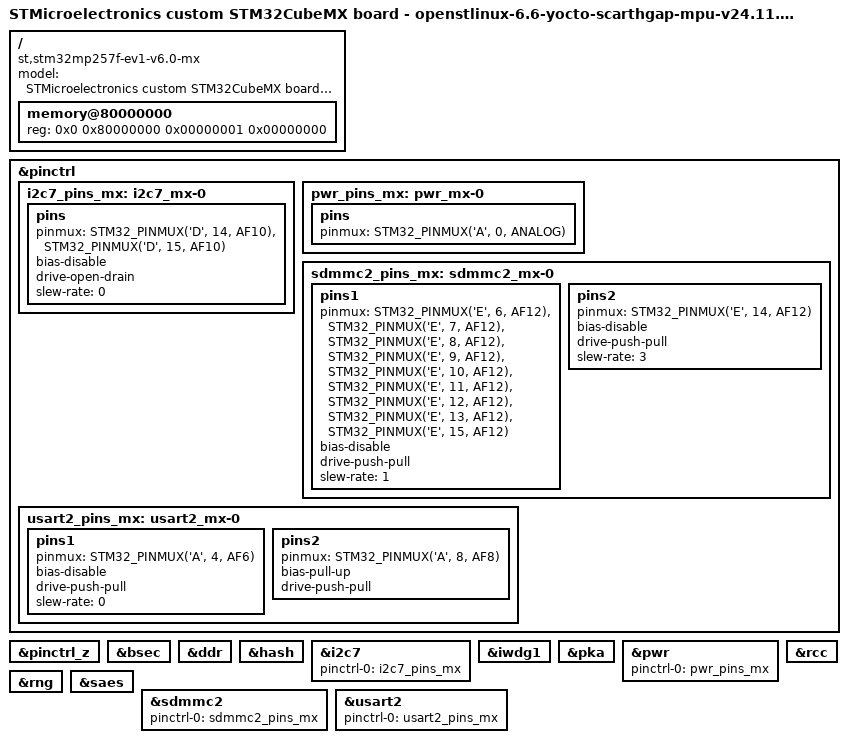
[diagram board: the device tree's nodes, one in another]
// SPDX-License-Identifier: (GPL-2.0-or-later OR BSD-3-Clause)
/*
 * Copyright (C) 2024, STMicroelectronics - All Rights Reserved
 * Author: STM32CubeMX code generation for STMicroelectronics.
 */

/* For more information on Device Tree configuration, please refer to
 * https://wiki.st.com/stm32mpu/wiki/Category:Device_tree_configuration
 */

/dts-v1/;

#include <dt-bindings/pinctrl/stm32-pinfunc.h>
#include <dt-bindings/clock/stm32mp25-clksrc.h>
#include "stm32mp25-mx.dtsi"

#include "stm32mp257.dtsi"
#include "stm32mp25xf.dtsi"
#include "stm32mp257f-ev1-v6.0-mx-rcc.dtsi"
#include "stm32mp25xxai-pinctrl.dtsi"
#include "stm32mp25-ddr.dtsi"

/* USER CODE BEGIN includes */
/* USER CODE END includes */

/ {
	model = "STMicroelectronics custom STM32CubeMX board - openstlinux-6.6-yocto-scarthgap-mpu-v24.11.06";
	compatible = "st,stm32mp257f-ev1-v6.0-mx", "st,stm32mp257";

	memory@80000000 {
		device_type = "memory";
		reg = <0x0 0x80000000 0x00000001 0x00000000>;

		/* USER CODE BEGIN memory */
		/* USER CODE END memory */
	};

	/* USER CODE BEGIN root */
	/* USER CODE END root */

}; /*root*/

&pinctrl {
	i2c7_pins_mx: i2c7_mx-0 {
		pins {
			pinmux = <STM32_PINMUX('D', 14, AF10)>, /* I2C7_SDA */
					 <STM32_PINMUX('D', 15, AF10)>; /* I2C7_SCL */
			bias-disable;
			drive-open-drain;
			slew-rate = <0>;
		};
	};

	pwr_pins_mx: pwr_mx-0 {
		pins {
			pinmux = <STM32_PINMUX('A', 0, ANALOG)>; /* PWR_WKUP1 */
		};
	};

	sdmmc2_pins_mx: sdmmc2_mx-0 {
		pins1 {
			pinmux = <STM32_PINMUX('E', 6, AF12)>, /* SDMMC2_D6 */
					 <STM32_PINMUX('E', 7, AF12)>, /* SDMMC2_D7 */
					 <STM32_PINMUX('E', 8, AF12)>, /* SDMMC2_D2 */
					 <STM32_PINMUX('E', 9, AF12)>, /* SDMMC2_D5 */
					 <STM32_PINMUX('E', 10, AF12)>, /* SDMMC2_D4 */
					 <STM32_PINMUX('E', 11, AF12)>, /* SDMMC2_D1 */
					 <STM32_PINMUX('E', 12, AF12)>, /* SDMMC2_D3 */
					 <STM32_PINMUX('E', 13, AF12)>, /* SDMMC2_D0 */
					 <STM32_PINMUX('E', 15, AF12)>; /* SDMMC2_CMD */
			bias-disable;
			drive-push-pull;
			slew-rate = <1>;
		};
		pins2 {
			pinmux = <STM32_PINMUX('E', 14, AF12)>; /* SDMMC2_CK */
			bias-disable;
			drive-push-pull;
			slew-rate = <3>;
		};
	};

	usart2_pins_mx: usart2_mx-0 {
		pins1 {
			pinmux = <STM32_PINMUX('A', 4, AF6)>; /* USART2_TX */
			bias-disable;
			drive-push-pull;
			slew-rate = <0>;
		};
		pins2 {
			pinmux = <STM32_PINMUX('A', 8, AF8)>; /* USART2_RX */
			bias-pull-up;
			drive-push-pull;
		};
	};

	/* USER CODE BEGIN pinctrl */
	/* USER CODE END pinctrl */
};

&pinctrl_z {
	/* USER CODE BEGIN pinctrl_z */
	/* USER CODE END pinctrl_z */
};

&bsec {
	status = "okay";

	/* USER CODE BEGIN bsec */
	/* USER CODE END bsec */
};

&ddr {
	status = "okay";

	/* USER CODE BEGIN ddr */
	/* USER CODE END ddr */
};

&hash {
	status = "okay";

	/* USER CODE BEGIN hash */
	/* USER CODE END hash */
};

&i2c7 {
	pinctrl-names = "default";
	pinctrl-0 = <&i2c7_pins_mx>;
	status = "okay";

	/* USER CODE BEGIN i2c7 */
	/* USER CODE END i2c7 */
};

&iwdg1 {
	status = "okay";

	/* USER CODE BEGIN iwdg1 */
	/* USER CODE END iwdg1 */
};

&pka {
	status = "okay";

	/* USER CODE BEGIN pka */
	/* USER CODE END pka */
};

&pwr {
	pinctrl-names = "default";
	pinctrl-0 = <&pwr_pins_mx>;
	status = "okay";

	/* USER CODE BEGIN pwr */
	/* USER CODE END pwr */
};

&rcc {
	status = "okay";

	/* USER CODE BEGIN rcc */
	/* USER CODE END rcc */
};

&rng {
	status = "okay";

	/* USER CODE BEGIN rng */
	/* USER CODE END rng */
};

&saes {
	status = "okay";

	/* USER CODE BEGIN saes */
	/* USER CODE END saes */
};

&sdmmc2 {
	pinctrl-names = "default";
	pinctrl-0 = <&sdmmc2_pins_mx>;
	status = "okay";

	/* USER CODE BEGIN sdmmc2 */
	/* USER CODE END sdmmc2 */
};

&usart2 {
	pinctrl-names = "default";
	pinctrl-0 = <&usart2_pins_mx>;
	status = "okay";

	/* USER CODE BEGIN usart2 */
	/* USER CODE END usart2 */
};

/* USER CODE BEGIN addons */
#include "stm32mp257f-ev1-v6.0-mx-usercodes.dtsi"
/* USER CODE END addons */

